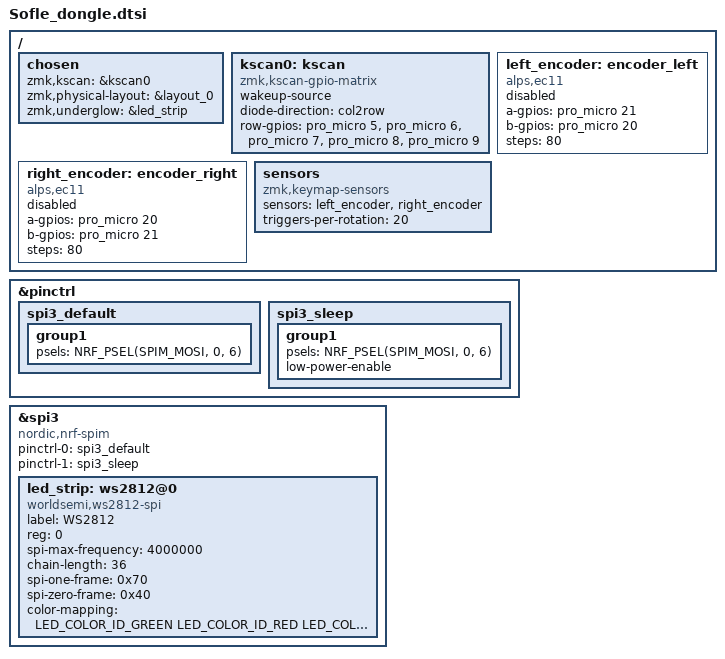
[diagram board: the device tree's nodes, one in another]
/*
 * Copyright (c) 2020 Pete Johanson, Ryan Cross
 *
 * SPDX-License-Identifier: MIT
 */

#include "Sofle_dongle-layouts.dtsi"
#include <dt-bindings/led/led.h>

/ {
    chosen {
        zmk,kscan = &kscan0;
        zmk,physical-layout = &layout_0;
    };

    kscan0: kscan {
        compatible = "zmk,kscan-gpio-matrix";
        wakeup-source;

        diode-direction = "col2row";
        row-gpios
            = <&pro_micro 5 (GPIO_ACTIVE_HIGH | GPIO_PULL_DOWN)>
            , <&pro_micro 6 (GPIO_ACTIVE_HIGH | GPIO_PULL_DOWN)>
            , <&pro_micro 7 (GPIO_ACTIVE_HIGH | GPIO_PULL_DOWN)>
            , <&pro_micro 8 (GPIO_ACTIVE_HIGH | GPIO_PULL_DOWN)>
            , <&pro_micro 9 (GPIO_ACTIVE_HIGH | GPIO_PULL_DOWN)>
            ;
    };

    left_encoder: encoder_left {
        compatible = "alps,ec11";
        a-gpios = <&pro_micro 21 (GPIO_ACTIVE_HIGH | GPIO_PULL_UP)>;
        b-gpios = <&pro_micro 20 (GPIO_ACTIVE_HIGH | GPIO_PULL_UP)>;
        steps = <80>;
        status = "disabled";
    };

    right_encoder: encoder_right {
        compatible = "alps,ec11";
        a-gpios = <&pro_micro 20 (GPIO_ACTIVE_HIGH | GPIO_PULL_UP)>;
        b-gpios = <&pro_micro 21 (GPIO_ACTIVE_HIGH | GPIO_PULL_UP)>;
        steps = <80>;
        status = "disabled";
    };

    sensors: sensors {
        compatible = "zmk,keymap-sensors";
        sensors = <&left_encoder &right_encoder>;
        triggers-per-rotation = <20>;
    };
};

// rgb,SPI
&pinctrl {
    spi3_default: spi3_default {
        group1 {
            psels = <NRF_PSEL(SPIM_MOSI, 0, 6)>;
        };
    };

    spi3_sleep: spi3_sleep {
        group1 {
            psels = <NRF_PSEL(SPIM_MOSI, 0, 6)>;
            low-power-enable;
		};
	};
};

&spi3 {
	compatible = "nordic,nrf-spim";
	status = "okay";

	pinctrl-0 = <&spi3_default>;
	pinctrl-1 = <&spi3_sleep>;
	pinctrl-names = "default", "sleep";


	led_strip: ws2812@0 {
		compatible = "worldsemi,ws2812-spi";
		label = "WS2812";

		/* SPI */
		reg = <0>; /* ignored, but necessary for SPI bindings */
		spi-max-frequency = <4000000>;

		/* WS2812 */
		chain-length = <36>; /* There are per-key RGB, but the first 6 are underglow */
		spi-one-frame = <0x70>;
		spi-zero-frame = <0x40>;
		color-mapping = <LED_COLOR_ID_GREEN LED_COLOR_ID_RED LED_COLOR_ID_BLUE>;
	};
};

/ {
	chosen {
		zmk,underglow = &led_strip;
	};
};
